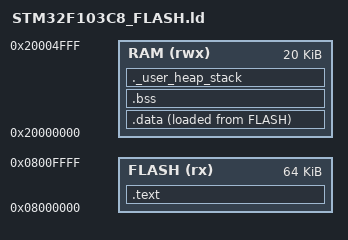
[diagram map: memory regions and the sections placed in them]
/* SPDX-License-Identifier: Apache-2.0 */
/**
 * Linker script for STM32F103C8
 * 64KB Flash, 20KB RAM
 */

/* Entry Point */
ENTRY(Reset_Handler)

/* Memory Regions */
MEMORY
{
    FLASH (rx)  : ORIGIN = 0x08000000, LENGTH = 64K
    RAM (rwx)   : ORIGIN = 0x20000000, LENGTH = 20K
}

/* Stack and Heap sizes */
_Min_Heap_Size = 0x200;
_Min_Stack_Size = 0x400;

/* Sections */
SECTIONS
{
    /* Vector table and code */
    .text :
    {
        . = ALIGN(4);
        KEEP(*(.isr_vector))
        *(.text)
        *(.text*)
        *(.rodata)
        *(.rodata*)
        . = ALIGN(4);
        _etext = .;
    } >FLASH

    /* Initialized data */
    .data :
    {
        . = ALIGN(4);
        _sdata = .;
        *(.data)
        *(.data*)
        . = ALIGN(4);
        _edata = .;
    } >RAM AT>FLASH

    _sidata = LOADADDR(.data);

    /* Uninitialized data */
    .bss :
    {
        . = ALIGN(4);
        _sbss = .;
        *(.bss)
        *(.bss*)
        *(COMMON)
        . = ALIGN(4);
        _ebss = .;
    } >RAM

    /* Heap and Stack */
    ._user_heap_stack :
    {
        . = ALIGN(8);
        PROVIDE(end = .);
        PROVIDE(_end = .);
        . = . + _Min_Heap_Size;
        . = . + _Min_Stack_Size;
        . = ALIGN(8);
    } >RAM
}
